# AT32A403Axx_v2 register map
Vendor: Keil; Series: AT32A403A; File version: 1.0
CPU: CM4 r0p1, little endian, no MPU, FPU, 4 interrupt priority bits
Registers are 32-bit, read-write, reset 0x0 unless marked. A register's access mark holds for its fields unless they carry their own. Offsets are from the block's base; [hi:lo] are bit positions.

## ETHERNET_MAC — Ethernet: media access control
Base 0x40028000
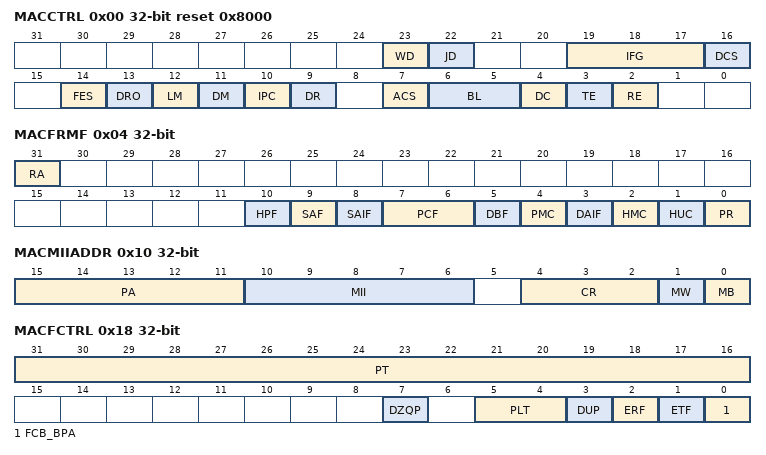
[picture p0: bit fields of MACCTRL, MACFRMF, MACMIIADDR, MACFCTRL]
0x00 MACCTRL reset 0x8000 — Ethernet MAC configuration register
  [23] WD — Watchdog disable
  [22] JD — Jabber disable
  [19:17] IFG — Interframe gap
  [16] DCS — Disable carrier sense
  [14] FES — Fast EMAC speed
  [13] DRO — Disable receive own
  [12] LM — Loopback mode
  [11] DM — Duplex mode
  [10] IPC — IPv4 checksum offload
  [9] DR — Disable retry
  [7] ACS — Automatic pad/CRC stripping
  [6:5] BL — Back-off limit
  [4] DC — Deferral check
  [3] TE — Transmitter enable
  [2] RE — Receiver enable
0x04 MACFRMF — Ethernet MAC frame filter register
  [31] RA — Receive all
  [10] HPF — Hash or perfect filter
  [9] SAF — Source address filter
  [8] SAIF — Source address inverse filtering
  [7:6] PCF — Pass control frames
  [5] DBF — Disable broadcast frames
  [4] PMC — Pass multicast
  [3] DAIF — Destination address inverse filtering
  [2] HMC — Hash multicast
  [1] HUC — Hash unicast
  [0] PR — Promiscuous mode
0x08 MACHTH — Ethernet MAC hash table high register
  [31:0] HTH — Hash table high
0x0C MACHTL — Ethernet MAC hash table low register
  [31:0] HTL — Hash table low
0x10 MACMIIADDR — Ethernet MAC MII address register
  [15:11] PA — PHY address
  [10:6] MII
  [4:2] CR — Clock range
  [1] MW — MII write
  [0] MB — MII busy
0x14 MACMIIDT — Ethernet MAC MII data register
  [15:0] MD — MII data
0x18 MACFCTRL — Ethernet MAC flow control register
  [31:16] PT — Pass time
  [7] DZQP — Disable zero-quanta pause
  [5:4] PLT — Pause low threshold
  [3] DUP — Detect unicast pause frame
  [2] ERF — Enable receive flow control
  [1] ETF — Enable transmit flow control
  [0] FCB_BPA — Flow control busy/back pressure activate
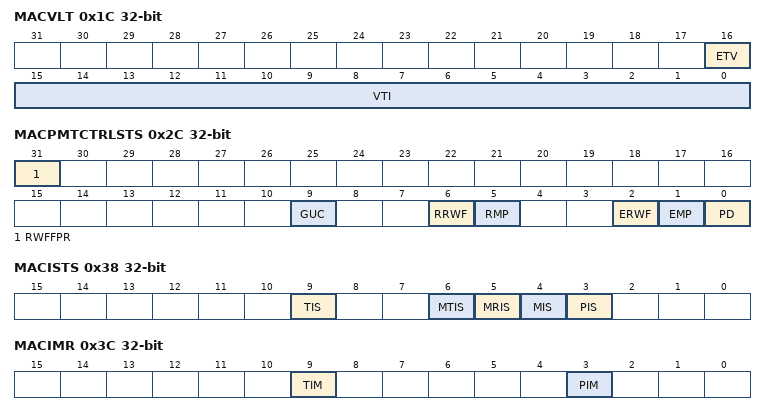
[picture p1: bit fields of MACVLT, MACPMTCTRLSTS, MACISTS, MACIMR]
0x1C MACVLT — Ethernet MAC VLAN tag register
  [16] ETV — Enable 12-bit VLAN tag comparison
  [15:0] VTI — VLAN tag identifier (for receive frames)
0x28 MACRWFF — Ethernet MAC remote wakeup frame filter register
0x2C MACPMTCTRLSTS — Ethernet MAC PMT control and status register
  [31] RWFFPR — Remote wakeup frame filter register pointer reset
  [9] GUC — Global unicast
  [6] RRWF — Recevied remote wakeup frame
  [5] RMP — Received magic packet
  [2] ERWF — Enable remote wakeup frame
  [1] EMP — Enable magic packet
  [0] PD — Power down
0x38 MACISTS — Ethernet MAC interrupt status register
  [9] TIS — Timestamp interrupt status
  [6] MTIS — MMC transmit interrupt status
  [5] MRIS — MMC receive interrupt status
  [4] MIS — MMC interrupt status
  [3] PIS — PMT interrupt status
0x3C MACIMR — Ethernet MAC interrupt mask register
  [9] TIM — Timestamp interrupt mask
  [3] PIM — PMT interrupt mask
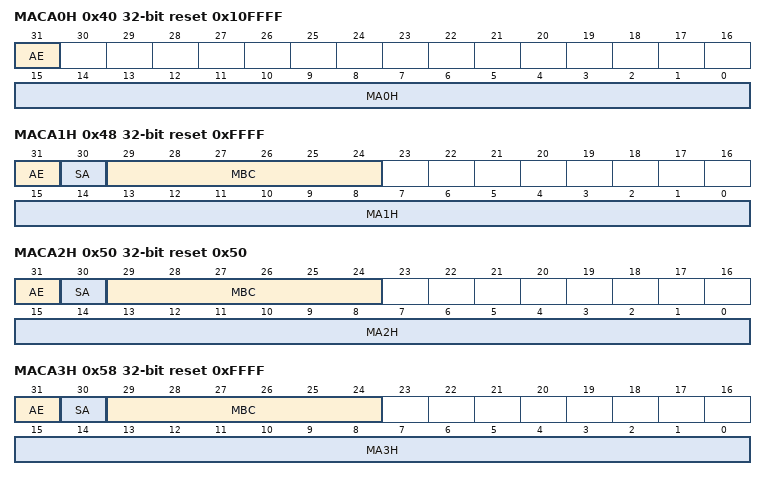
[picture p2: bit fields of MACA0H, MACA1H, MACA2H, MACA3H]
0x40 MACA0H reset 0x10FFFF — Ethernet MAC address 0 high register
  [31] AE ro — Address enable
  [15:0] MA0H — MAC address0 high
0x44 MACA0L reset 0xFFFFFFFF — Ethernet MAC address 0 low register
  [31:0] MA0L — MAC address0 low
0x48 MACA1H reset 0xFFFF — Ethernet MAC address 1 high register
  [31] AE — Address enable
  [30] SA — Source address
  [29:24] MBC — Mask byte control
  [15:0] MA1H — MAC address1 high
0x4C MACA1L reset 0xFFFFFFFF — Ethernet MAC address1 low register
  [31:0] MA1L — MAC address1 low
0x50 MACA2H reset 0x50 — Ethernet MAC address 2 high register
  [31] AE — Address enable
  [30] SA — Source address
  [29:24] MBC — Mask byte control
  [15:0] MA2H — MAC address 2 high
0x54 MACA2L reset 0xFFFFFFFF — Ethernet MAC address 2 low register
  [30:0] MA2L — MAC address2 low
0x58 MACA3H reset 0xFFFF — Ethernet MAC address 3 high register
  [31] AE — Address enable
  [30] SA — Source address
  [29:24] MBC — Mask byte control
  [15:0] MA3H — MAC address3 high
0x5C MACA3L reset 0xFFFFFFFF — Ethernet MAC address 3 low register
  [31:0] MA3L — MAC address3 low
